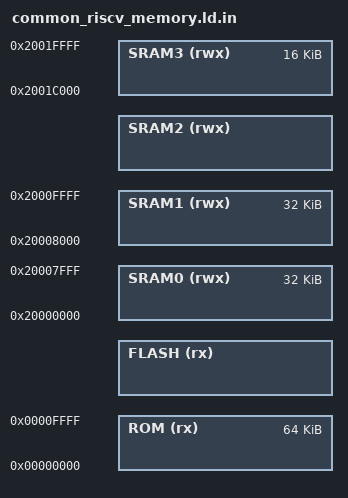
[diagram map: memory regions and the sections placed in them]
/* Auto-generated by maxim_add_riscv_coprocessor(). */
_FlashLength_ = __FlashLength;

MEMORY {
    ROM     (rx)  : ORIGIN = 0x00000000, LENGTH = 0x00010000
    FLASH   (rx)  : ORIGIN = __FlashStart, LENGTH = _FlashLength_
    SRAM0   (rwx) : ORIGIN = 0x20000000, LENGTH = 0x00008000
    SRAM1   (rwx) : ORIGIN = 0x20008000, LENGTH = 0x00008000
    SRAM2   (rwx) : ORIGIN = @_rv_sram2_origin@, LENGTH = @_rv_sram2_length@
    SRAM3   (rwx) : ORIGIN = 0x2001C000, LENGTH = 0x00004000
}
